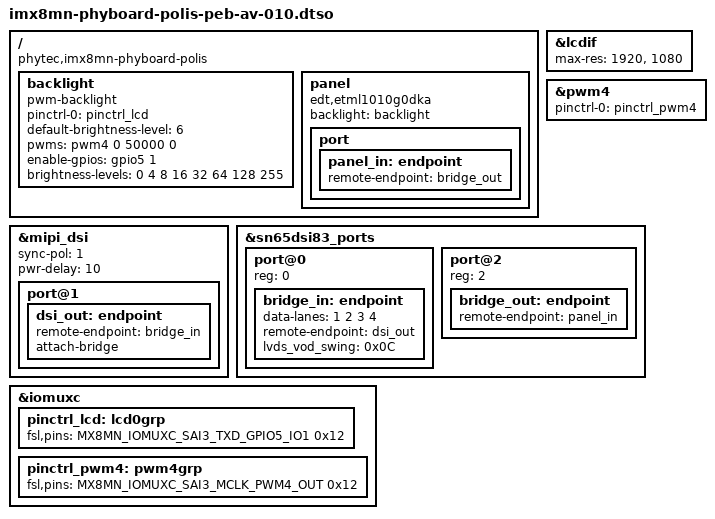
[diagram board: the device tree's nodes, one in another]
// SPDX-License-Identifier: GPL-2.0
/*
 * Copyright (C) 2020 PHYTEC Messtechnik GmbH
 * Author: Teresa Remmet <t.remmet@phytec.de>
 */

/dts-v1/;
/plugin/;

#include <dt-bindings/clock/imx8mn-clock.h>
#include <dt-bindings/gpio/gpio.h>
#include "../imx8mn-pinfunc.h"

/ {
	compatible = "phytec,imx8mn-phyboard-polis";

	fragment@6 {
		target-path= "/";

		__overlay__ {
			backlight: backlight {
				compatible = "pwm-backlight";
				pinctrl-names = "default";
				pinctrl-0 = <&pinctrl_lcd>;
				default-brightness-level = <6>;
				pwms = <&pwm4 0 50000 0>;
				enable-gpios = <&gpio5 1 GPIO_ACTIVE_HIGH>;
				brightness-levels= <0 4 8 16 32 64 128 255>;
			};

			panel {
				compatible = "edt,etml1010g0dka";
				backlight = <&backlight>;

				port {
					panel_in: endpoint {
						remote-endpoint = <&bridge_out>;
					};
				};
			};
		};
	};
};

&lcdif {
	max-res = <1920>, <1080>;
	status = "okay";
};

&mipi_dsi {
	sync-pol = <1>;
	pwr-delay = <10>;
	status = "okay";

	#address-cells = <1>;
	#size-cells = <0>;

	port@1 {
		dsi_out: endpoint {
			remote-endpoint = <&bridge_in>;
			attach-bridge;
		};
	};
};

&pwm4 {
	pinctrl-names = "default";
	pinctrl-0 = <&pinctrl_pwm4>;
	status = "okay";
};

&sn65dsi83_ports {

	#address-cells = <1>;
	#size-cells = <0>;

	port@0 {
		reg = <0>;

		bridge_in: endpoint {
			data-lanes = <1 2 3 4>;
			remote-endpoint = <&dsi_out>;
			lvds_vod_swing = <0x0C>;
		};

	};

	port@2 {
		reg = <2>;

		bridge_out: endpoint {
			remote-endpoint = <&panel_in>;
		};
	};
};

&iomuxc {
	pinctrl_lcd: lcd0grp {
		fsl,pins = <
			MX8MN_IOMUXC_SAI3_TXD_GPIO5_IO1                 0x12
		>;
	};

	pinctrl_pwm4: pwm4grp {
		fsl,pins = <
			MX8MN_IOMUXC_SAI3_MCLK_PWM4_OUT			0x12
		>;
	};
};
